VERSION ""

NS_ :

BS_:

BU_: ControlUnit Seat
VAL_TABLE_ SVariant 1 "Comfort" 0 "Basis" ;

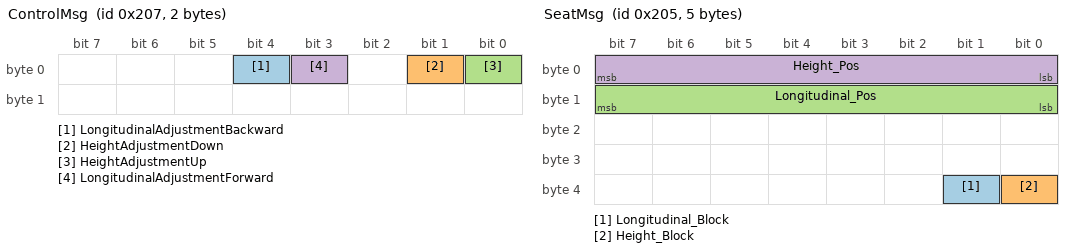
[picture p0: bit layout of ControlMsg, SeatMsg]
BO_ 519 ControlMsg: 2 ControlUnit
 SG_ LongitudinalAdjustmentBackward : 4|1@1+ (1,0) [0|1] "" Vector__XXX
 SG_ HeightAdjustmentDown : 1|1@1+ (1,0) [0|1] "" Vector__XXX
 SG_ HeightAdjustmentUp : 0|1@1+ (1,0) [0|1] ""  Seat
 SG_ LongitudinalAdjustmentForward : 3|1@1+ (1,0) [0|1] ""  Seat

BO_ 517 SeatMsg: 5 Seat
 SG_ Longitudinal_Block : 33|1@1+ (1,0) [0|1] ""  ControlUnit
 SG_ Height_Block : 32|1@1+ (1,0) [0|1] ""  ControlUnit
 SG_ Longitudinal_Pos : 8|8@1+ (1,0) [0|255] ""  ControlUnit
 SG_ Height_Pos : 0|8@1+ (1,0) [0|255] ""  ControlUnit

BA_DEF_ SG_  "GenSigSendType" ENUM  "Cyclic","OnWrite","OnWriteWithRepetition","OnChange";
BA_DEF_ BO_  "GenMsgILSupport" ENUM  "No","Yes";
BA_DEF_ BU_  "ILUsed" ENUM  "Yes","No";
BA_DEF_ BO_  "GenMsgSendType" ENUM  "Cyclic","NotUsed","NotUsed","NotUsed","NotUsed","Cyclic","NotUsed","IfActive","NoMsgSendType","NotUsed";
BA_DEF_ BO_  "GenMsgStartDelayTime" INT 0 0;
BA_DEF_ BO_  "GenMsgCycleTime" INT 0 0;
BA_DEF_  "BusType" STRING ;
BA_DEF_ BU_  "NodeLayerModules" STRING ;
BA_DEF_DEF_  "GenSigSendType" "Cyclic";
BA_DEF_DEF_  "GenMsgILSupport" "Yes";
BA_DEF_DEF_  "ILUsed" "Yes";
BA_DEF_DEF_  "GenMsgSendType" "NoMsgSendType";
BA_DEF_DEF_  "GenMsgStartDelayTime" 0;
BA_DEF_DEF_  "GenMsgCycleTime" 0;
BA_DEF_DEF_  "BusType" "CAN";
BA_DEF_DEF_  "NodeLayerModules" "CANoeILNLVector.dll";
BA_ "NodeLayerModules" BU_ Seat "CANoeILNLVector.dll,osek_tp.dll";
BA_ "GenMsgCycleTime" BO_ 519 100;
BA_ "GenMsgSendType" BO_ 519 0;
BA_ "GenMsgCycleTime" BO_ 517 100;
BA_ "GenMsgStartDelayTime" BO_ 517 50;
BA_ "GenSigSendType" SG_ 519 LongitudinalAdjustmentBackward 3;
BA_ "GenSigSendType" SG_ 519 HeightAdjustmentDown 3;
BA_ "GenSigSendType" SG_ 519 HeightAdjustmentUp 3;
BA_ "GenSigSendType" SG_ 519 LongitudinalAdjustmentForward 3;
